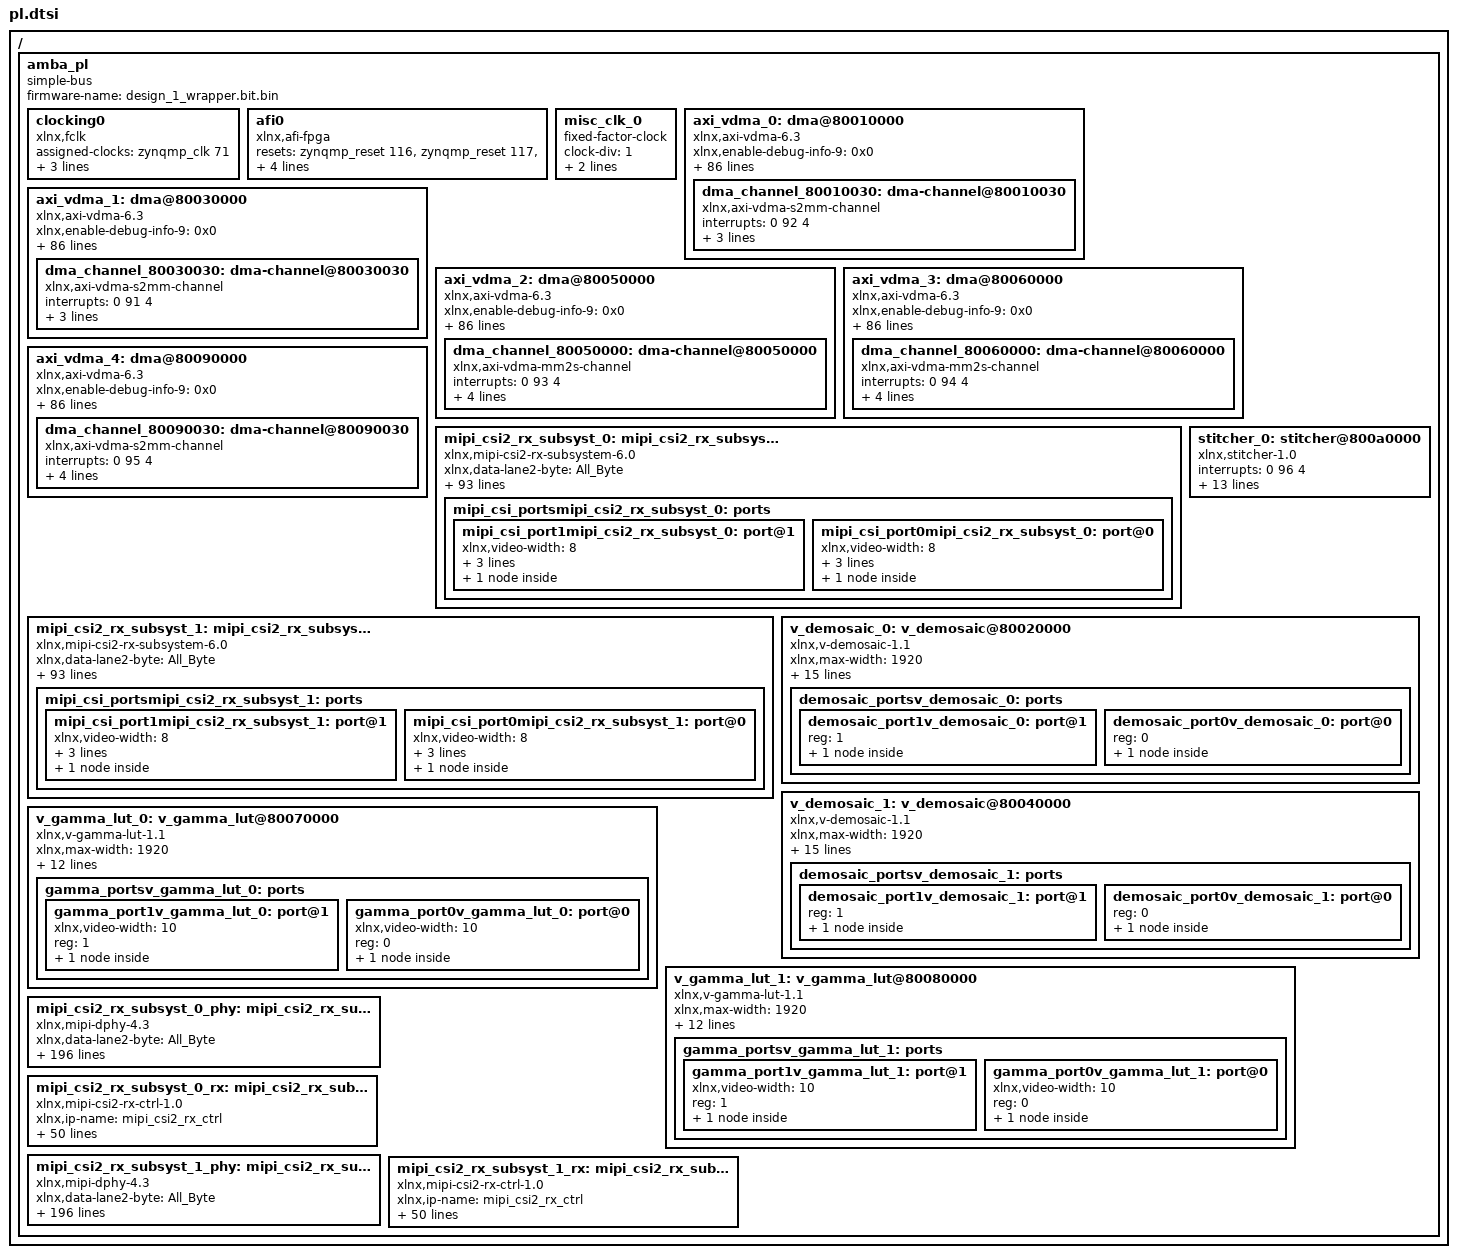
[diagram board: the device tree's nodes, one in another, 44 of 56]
/ {
	amba_pl: amba_pl {
		ranges;
		compatible = "simple-bus";
		#address-cells = <2>;
		#size-cells = <2>;
		firmware-name = "design_1_wrapper.bit.bin";
		clocking0: clocking0 {
			compatible = "xlnx,fclk";
			status = "okay";
			assigned-clocks = <&zynqmp_clk 71>;
			assigned-clock-rates = <149998505>;
			#clock-cells = <0>;
			clock-output-names = "fabric_clk";
			clocks = <&zynqmp_clk 71>;
		};
		afi0: afi0 {
			status = "okay";
			compatible = "xlnx,afi-fpga";
			resets = <&zynqmp_reset 116>, <&zynqmp_reset 117>, <&zynqmp_reset 118>, <&zynqmp_reset 119>;
			config-afi = < 0 0>, <1 0>, <2 0>, <3 0>, <4 0>, <5 0>, <6 0>, <7 0>, <8 0>, <9 0>, <10 0>, <11 0>, <12 0>, <13 0>, <14 0xa00>, <15 0x000>;
		};
		misc_clk_0: misc_clk_0 {
			clock-div = <1>;
			compatible = "fixed-factor-clock";
			clock-mult = <1>;
			clocks = <&zynqmp_clk 71>;
			#clock-cells = <0>;
		};
		axi_vdma_0: dma@80010000 {
			xlnx,enable-debug-info-9 = <0x0>;
			xlnx,enable-s2mm-frm-counter = <1>;
			xlnx,enable-mm2s-delay-counter = <1>;
			xlnx,dlytmr-resolution = <125>;
			xlnx,enable-s2mm-buf-full = <0>;
			xlnx,ip-name = "axi_vdma";
			xlnx,s2mm-genlock-num-masters = <1>;
			reg = <0x0 0x80010000 0x0 0x10000>;
			xlnx,enable-s2mm-fsync-out = <0>;
			xlnx,use-mm2s-fsync = <0>;
			xlnx,s2mm-linebuffer-thresh = <4>;
			xlnx,enable-mm2s-frm-counter = <1>;
			xlnx,m-axis-mm2s-tdata-width = <32>;
			xlnx,enable-all = <0>;
			xlnx,dynamic-resolution = <1>;
			xlnx,enable-s2mm-rst-out = <0>;
			interrupt-names = "s2mm_introut";
			xlnx,s2mm-sof-enable = <0x1>;
			xlnx,mm2s-genlock-num-masters = <1>;
			xlnx,enable-mm2s-fsync-out = <0>;
			xlnx,mm2s-linebuffer-thresh = <4>;
			compatible = "xlnx,axi-vdma-6.3" , "xlnx,axi-vdma-1.00.a";
			xlnx,enable-tstvec = <0>;
			interrupt-parent = <&imux>;
			xlnx,s2mm-max-burst-length = <128>;
			xlnx,enable-mm2s-rst-out = <0>;
			xlnx,mm2s-sof-enable = <1>;
			xlnx,include-s2mm-dre = <0x1>;
			xlnx,enable-s2mm-frmstr-reg = <0>;
			xlnx,m-axi-s2mm-data-width = <64>;
			xlnx,enable-s2mm-sts-reg = <0>;
			xlnx,mm2s-max-burst-length = <8>;
			status = "okay";
			xlnx,include-mm2s-dre = <0x0>;
			xlnx,name = "axi_vdma_0";
			xlnx,enable-mm2s-frmstr-reg = <0>;
			interrupts = < 0 92 4 >;
			xlnx,m-axi-mm2s-data-width = <64>;
			xlnx,flush-on-fsync = <0x1>;
			xlnx,include-s2mm-sf = <1>;
			xlnx,single-interface = <0>;
			xlnx,s2mm-linebuffer-depth = <0x400>;
			xlnx,include-s2mm = <0x1>;
			xlnx,addr-width = <32>;
			clocks = <&zynqmp_clk 71>, <&zynqmp_clk 71>, <&zynqmp_clk 71>;
			xlnx,s-axis-s2mm-tdata-width = <32>;
			xlnx,enable-debug-info-10 = <0>;
			xlnx,addrwidth = <0x20>;
			xlnx,enable-debug-info-11 = <0>;
			xlnx,edk-iptype = "PERIPHERAL";
			xlnx,enable-debug-info-12 = <0>;
			xlnx,use-fsync = <1>;
			xlnx,s2mm-genlock-repeat-en = <1>;
			xlnx,enable-debug-info-13 = <0x0>;
			xlnx,enable-vert-flip = <0x0>;
			xlnx,include-mm2s-sf = <0>;
			xlnx,enable-debug-info-14 = <0x1>;
			xlnx,include-internal-genlock = <0x1>;
			clock-names = "m_axi_s2mm_aclk" , "s_axi_lite_aclk" , "s_axis_s2mm_aclk";
			xlnx,enable-debug-info-15 = <0x1>;
			xlnx,mm2s-linebuffer-depth = <0x200>;
			xlnx,include-mm2s = <0x0>;
			xlnx,s2mm-genlock-mode = <0x0>;
			xlnx,flush-fsync = <0x1>;
			xlnx,select-xpm = <0>;
			xlnx,s2mm-data-width = <0x40>;
			xlnx,num-fstores = <0x3>;
			xlnx,enable-s2mm-param-updt = <0>;
			xlnx,enable-vidparam-reads = <0x1>;
			xlnx,mm2s-genlock-repeat-en = <0>;
			xlnx,prmry-is-aclk-async = <0>;
			xlnx,s2mm-tdata-width = <0x20>;
			#dma-cells = <1>;
			xlnx,enable-vidprmtr-reads = <1>;
			xlnx,mm2s-genlock-mode = <0x0>;
			xlnx,enable-debug-info-0 = <0>;
			xlnx,enable-debug-all = <0x0>;
			xlnx,enable-debug-info-1 = <0x0>;
			xlnx,mm2s-data-width = <0x40>;
			xlnx,enable-debug-info-2 = <0>;
			xlnx,enable-mm2s-param-updt = <0>;
			xlnx,enable-debug-info-3 = <0>;
			xlnx,enable-s2mm-delay-counter = <1>;
			xlnx,enable-debug-info-4 = <0>;
			xlnx,enable-debug-info-5 = <0x0>;
			xlnx,mm2s-tdata-width = <0x20>;
			xlnx,enable-debug-info-6 = <0x1>;
			xlnx,enable-debug-info-7 = <0x1>;
			xlnx,use-s2mm-fsync = <2>;
			xlnx,enable-debug-info-8 = <0>;
			xlnx,enable-mm2s-buf-empty = <0>;
			dma_channel_80010030: dma-channel@80010030 {
				interrupts = < 0 92 4 >;
				xlnx,datawidth = <0x20>;
				xlnx,device-id = <0x0>;
				compatible = "xlnx,axi-vdma-s2mm-channel";
				xlnx,include-dre;
			};
		};
		axi_vdma_1: dma@80030000 {
			xlnx,enable-debug-info-9 = <0x0>;
			xlnx,enable-s2mm-frm-counter = <1>;
			xlnx,enable-mm2s-delay-counter = <1>;
			xlnx,dlytmr-resolution = <125>;
			xlnx,enable-s2mm-buf-full = <0>;
			xlnx,ip-name = "axi_vdma";
			xlnx,s2mm-genlock-num-masters = <1>;
			reg = <0x0 0x80030000 0x0 0x10000>;
			xlnx,enable-s2mm-fsync-out = <0>;
			xlnx,use-mm2s-fsync = <0>;
			xlnx,s2mm-linebuffer-thresh = <4>;
			xlnx,enable-mm2s-frm-counter = <1>;
			xlnx,m-axis-mm2s-tdata-width = <32>;
			xlnx,enable-all = <0>;
			xlnx,dynamic-resolution = <1>;
			xlnx,enable-s2mm-rst-out = <0>;
			interrupt-names = "s2mm_introut";
			xlnx,s2mm-sof-enable = <0x1>;
			xlnx,mm2s-genlock-num-masters = <1>;
			xlnx,enable-mm2s-fsync-out = <0>;
			xlnx,mm2s-linebuffer-thresh = <4>;
			compatible = "xlnx,axi-vdma-6.3" , "xlnx,axi-vdma-1.00.a";
			xlnx,enable-tstvec = <0>;
			interrupt-parent = <&imux>;
			xlnx,s2mm-max-burst-length = <128>;
			xlnx,enable-mm2s-rst-out = <0>;
			xlnx,mm2s-sof-enable = <1>;
			xlnx,include-s2mm-dre = <0x1>;
			xlnx,enable-s2mm-frmstr-reg = <0>;
			xlnx,m-axi-s2mm-data-width = <64>;
			xlnx,enable-s2mm-sts-reg = <0>;
			xlnx,mm2s-max-burst-length = <8>;
			status = "okay";
			xlnx,include-mm2s-dre = <0x0>;
			xlnx,name = "axi_vdma_1";
			xlnx,enable-mm2s-frmstr-reg = <0>;
			interrupts = < 0 91 4 >;
			xlnx,m-axi-mm2s-data-width = <64>;
			xlnx,flush-on-fsync = <0x1>;
			xlnx,include-s2mm-sf = <1>;
			xlnx,single-interface = <0>;
			xlnx,s2mm-linebuffer-depth = <0x400>;
			xlnx,include-s2mm = <0x1>;
			xlnx,addr-width = <32>;
			clocks = <&zynqmp_clk 71>, <&zynqmp_clk 71>, <&zynqmp_clk 71>;
			xlnx,s-axis-s2mm-tdata-width = <32>;
			xlnx,enable-debug-info-10 = <0>;
			xlnx,addrwidth = <0x20>;
			xlnx,enable-debug-info-11 = <0>;
			xlnx,edk-iptype = "PERIPHERAL";
			xlnx,enable-debug-info-12 = <0>;
			xlnx,use-fsync = <1>;
			xlnx,s2mm-genlock-repeat-en = <1>;
			xlnx,enable-debug-info-13 = <0x0>;
			xlnx,enable-vert-flip = <0x0>;
			xlnx,include-mm2s-sf = <0>;
			xlnx,enable-debug-info-14 = <0x1>;
			xlnx,include-internal-genlock = <0x1>;
			clock-names = "m_axi_s2mm_aclk" , "s_axi_lite_aclk" , "s_axis_s2mm_aclk";
			xlnx,enable-debug-info-15 = <0x1>;
			xlnx,mm2s-linebuffer-depth = <0x200>;
			xlnx,include-mm2s = <0x0>;
			xlnx,s2mm-genlock-mode = <0x0>;
			xlnx,flush-fsync = <0x1>;
			xlnx,select-xpm = <0>;
			xlnx,s2mm-data-width = <0x40>;
			xlnx,num-fstores = <0x3>;
			xlnx,enable-s2mm-param-updt = <0>;
			xlnx,enable-vidparam-reads = <0x1>;
			xlnx,mm2s-genlock-repeat-en = <0>;
			xlnx,prmry-is-aclk-async = <0>;
			xlnx,s2mm-tdata-width = <0x20>;
			#dma-cells = <1>;
			xlnx,enable-vidprmtr-reads = <1>;
			xlnx,mm2s-genlock-mode = <0x0>;
			xlnx,enable-debug-info-0 = <0>;
			xlnx,enable-debug-all = <0x0>;
			xlnx,enable-debug-info-1 = <0x0>;
			xlnx,mm2s-data-width = <0x40>;
			xlnx,enable-debug-info-2 = <0>;
			xlnx,enable-mm2s-param-updt = <0>;
			xlnx,enable-debug-info-3 = <0>;
			xlnx,enable-s2mm-delay-counter = <1>;
			xlnx,enable-debug-info-4 = <0>;
			xlnx,enable-debug-info-5 = <0x0>;
			xlnx,mm2s-tdata-width = <0x20>;
			xlnx,enable-debug-info-6 = <0x1>;
			xlnx,enable-debug-info-7 = <0x1>;
			xlnx,use-s2mm-fsync = <2>;
			xlnx,enable-debug-info-8 = <0>;
			xlnx,enable-mm2s-buf-empty = <0>;
			dma_channel_80030030: dma-channel@80030030 {
				interrupts = < 0 91 4 >;
				xlnx,datawidth = <0x20>;
				xlnx,device-id = <0x1>;
				compatible = "xlnx,axi-vdma-s2mm-channel";
				xlnx,include-dre;
			};
		};
		axi_vdma_2: dma@80050000 {
			xlnx,enable-debug-info-9 = <0x0>;
			xlnx,enable-s2mm-frm-counter = <1>;
			xlnx,enable-mm2s-delay-counter = <1>;
			xlnx,dlytmr-resolution = <125>;
			xlnx,enable-s2mm-buf-full = <0>;
			xlnx,ip-name = "axi_vdma";
			xlnx,s2mm-genlock-num-masters = <1>;
			reg = <0x0 0x80050000 0x0 0x10000>;
			xlnx,enable-s2mm-fsync-out = <0>;
			xlnx,use-mm2s-fsync = <0>;
			xlnx,s2mm-linebuffer-thresh = <4>;
			xlnx,enable-mm2s-frm-counter = <1>;
			xlnx,m-axis-mm2s-tdata-width = <32>;
			xlnx,enable-all = <0>;
			xlnx,dynamic-resolution = <1>;
			xlnx,enable-s2mm-rst-out = <0>;
			interrupt-names = "mm2s_introut";
			xlnx,s2mm-sof-enable = <0x1>;
			xlnx,mm2s-genlock-num-masters = <1>;
			xlnx,enable-mm2s-fsync-out = <0>;
			xlnx,mm2s-linebuffer-thresh = <4>;
			compatible = "xlnx,axi-vdma-6.3" , "xlnx,axi-vdma-1.00.a";
			xlnx,enable-tstvec = <0>;
			interrupt-parent = <&imux>;
			xlnx,s2mm-max-burst-length = <8>;
			xlnx,enable-mm2s-rst-out = <0>;
			xlnx,mm2s-sof-enable = <1>;
			xlnx,include-s2mm-dre = <0x0>;
			xlnx,enable-s2mm-frmstr-reg = <0>;
			xlnx,m-axi-s2mm-data-width = <64>;
			xlnx,enable-s2mm-sts-reg = <0>;
			xlnx,mm2s-max-burst-length = <128>;
			status = "okay";
			xlnx,include-mm2s-dre = <0x1>;
			xlnx,name = "axi_vdma_2";
			xlnx,enable-mm2s-frmstr-reg = <0>;
			interrupts = < 0 93 4 >;
			xlnx,m-axi-mm2s-data-width = <64>;
			xlnx,flush-on-fsync = <0x1>;
			xlnx,include-s2mm-sf = <1>;
			xlnx,single-interface = <0>;
			xlnx,s2mm-linebuffer-depth = <0x200>;
			xlnx,include-s2mm = <0x0>;
			xlnx,addr-width = <32>;
			clocks = <&zynqmp_clk 71>, <&zynqmp_clk 71>, <&zynqmp_clk 71>;
			xlnx,s-axis-s2mm-tdata-width = <32>;
			xlnx,enable-debug-info-10 = <0>;
			xlnx,addrwidth = <0x20>;
			xlnx,enable-debug-info-11 = <0>;
			xlnx,edk-iptype = "PERIPHERAL";
			xlnx,enable-debug-info-12 = <0>;
			xlnx,use-fsync = <1>;
			xlnx,s2mm-genlock-repeat-en = <1>;
			xlnx,enable-debug-info-13 = <0x0>;
			xlnx,enable-vert-flip = <0x0>;
			xlnx,include-mm2s-sf = <0>;
			xlnx,enable-debug-info-14 = <0x1>;
			xlnx,include-internal-genlock = <0x1>;
			clock-names = "m_axi_mm2s_aclk" , "m_axis_mm2s_aclk" , "s_axi_lite_aclk";
			xlnx,enable-debug-info-15 = <0x1>;
			xlnx,mm2s-linebuffer-depth = <0x400>;
			xlnx,include-mm2s = <0x1>;
			xlnx,s2mm-genlock-mode = <0x0>;
			xlnx,flush-fsync = <0x1>;
			xlnx,select-xpm = <0>;
			xlnx,s2mm-data-width = <0x40>;
			xlnx,num-fstores = <0x3>;
			xlnx,enable-s2mm-param-updt = <0>;
			xlnx,enable-vidparam-reads = <0x1>;
			xlnx,mm2s-genlock-repeat-en = <0>;
			xlnx,prmry-is-aclk-async = <0>;
			xlnx,s2mm-tdata-width = <0x20>;
			#dma-cells = <1>;
			xlnx,enable-vidprmtr-reads = <1>;
			xlnx,mm2s-genlock-mode = <0x3>;
			xlnx,enable-debug-info-0 = <0>;
			xlnx,enable-debug-all = <0x0>;
			xlnx,enable-debug-info-1 = <0x0>;
			xlnx,mm2s-data-width = <0x40>;
			xlnx,enable-debug-info-2 = <0>;
			xlnx,enable-mm2s-param-updt = <0>;
			xlnx,enable-debug-info-3 = <0>;
			xlnx,enable-s2mm-delay-counter = <1>;
			xlnx,enable-debug-info-4 = <0>;
			xlnx,enable-debug-info-5 = <0x0>;
			xlnx,mm2s-tdata-width = <0x20>;
			xlnx,enable-debug-info-6 = <0x1>;
			xlnx,enable-debug-info-7 = <0x1>;
			xlnx,use-s2mm-fsync = <2>;
			xlnx,enable-debug-info-8 = <0>;
			xlnx,enable-mm2s-buf-empty = <0>;
			dma_channel_80050000: dma-channel@80050000 {
				interrupts = < 0 93 4 >;
				xlnx,datawidth = <0x20>;
				xlnx,device-id = <0x2>;
				compatible = "xlnx,axi-vdma-mm2s-channel";
				xlnx,include-dre;
				xlnx,genlock-mode;
			};
		};
		axi_vdma_3: dma@80060000 {
			xlnx,enable-debug-info-9 = <0x0>;
			xlnx,enable-s2mm-frm-counter = <1>;
			xlnx,enable-mm2s-delay-counter = <1>;
			xlnx,dlytmr-resolution = <125>;
			xlnx,enable-s2mm-buf-full = <0>;
			xlnx,ip-name = "axi_vdma";
			xlnx,s2mm-genlock-num-masters = <1>;
			reg = <0x0 0x80060000 0x0 0x10000>;
			xlnx,enable-s2mm-fsync-out = <0>;
			xlnx,use-mm2s-fsync = <0>;
			xlnx,s2mm-linebuffer-thresh = <4>;
			xlnx,enable-mm2s-frm-counter = <1>;
			xlnx,m-axis-mm2s-tdata-width = <32>;
			xlnx,enable-all = <0>;
			xlnx,dynamic-resolution = <1>;
			xlnx,enable-s2mm-rst-out = <0>;
			interrupt-names = "mm2s_introut";
			xlnx,s2mm-sof-enable = <0x1>;
			xlnx,mm2s-genlock-num-masters = <1>;
			xlnx,enable-mm2s-fsync-out = <0>;
			xlnx,mm2s-linebuffer-thresh = <4>;
			compatible = "xlnx,axi-vdma-6.3" , "xlnx,axi-vdma-1.00.a";
			xlnx,enable-tstvec = <0>;
			interrupt-parent = <&imux>;
			xlnx,s2mm-max-burst-length = <8>;
			xlnx,enable-mm2s-rst-out = <0>;
			xlnx,mm2s-sof-enable = <1>;
			xlnx,include-s2mm-dre = <0x0>;
			xlnx,enable-s2mm-frmstr-reg = <0>;
			xlnx,m-axi-s2mm-data-width = <64>;
			xlnx,enable-s2mm-sts-reg = <0>;
			xlnx,mm2s-max-burst-length = <128>;
			status = "okay";
			xlnx,include-mm2s-dre = <0x1>;
			xlnx,name = "axi_vdma_3";
			xlnx,enable-mm2s-frmstr-reg = <0>;
			interrupts = < 0 94 4 >;
			xlnx,m-axi-mm2s-data-width = <64>;
			xlnx,flush-on-fsync = <0x1>;
			xlnx,include-s2mm-sf = <1>;
			xlnx,single-interface = <0>;
			xlnx,s2mm-linebuffer-depth = <0x200>;
			xlnx,include-s2mm = <0x0>;
			xlnx,addr-width = <32>;
			clocks = <&zynqmp_clk 71>, <&zynqmp_clk 71>, <&zynqmp_clk 71>;
			xlnx,s-axis-s2mm-tdata-width = <32>;
			xlnx,enable-debug-info-10 = <0>;
			xlnx,addrwidth = <0x20>;
			xlnx,enable-debug-info-11 = <0>;
			xlnx,edk-iptype = "PERIPHERAL";
			xlnx,enable-debug-info-12 = <0>;
			xlnx,use-fsync = <1>;
			xlnx,s2mm-genlock-repeat-en = <1>;
			xlnx,enable-debug-info-13 = <0x0>;
			xlnx,enable-vert-flip = <0x0>;
			xlnx,include-mm2s-sf = <0>;
			xlnx,enable-debug-info-14 = <0x1>;
			xlnx,include-internal-genlock = <0x1>;
			clock-names = "m_axi_mm2s_aclk" , "m_axis_mm2s_aclk" , "s_axi_lite_aclk";
			xlnx,enable-debug-info-15 = <0x1>;
			xlnx,mm2s-linebuffer-depth = <0x400>;
			xlnx,include-mm2s = <0x1>;
			xlnx,s2mm-genlock-mode = <0x0>;
			xlnx,flush-fsync = <0x1>;
			xlnx,select-xpm = <0>;
			xlnx,s2mm-data-width = <0x40>;
			xlnx,num-fstores = <0x3>;
			xlnx,enable-s2mm-param-updt = <0>;
			xlnx,enable-vidparam-reads = <0x1>;
			xlnx,mm2s-genlock-repeat-en = <0>;
			xlnx,prmry-is-aclk-async = <0>;
			xlnx,s2mm-tdata-width = <0x20>;
			#dma-cells = <1>;
			xlnx,enable-vidprmtr-reads = <1>;
			xlnx,mm2s-genlock-mode = <0x3>;
			xlnx,enable-debug-info-0 = <0>;
			xlnx,enable-debug-all = <0x0>;
			xlnx,enable-debug-info-1 = <0x0>;
			xlnx,mm2s-data-width = <0x40>;
			xlnx,enable-debug-info-2 = <0>;
			xlnx,enable-mm2s-param-updt = <0>;
			xlnx,enable-debug-info-3 = <0>;
			xlnx,enable-s2mm-delay-counter = <1>;
			xlnx,enable-debug-info-4 = <0>;
			xlnx,enable-debug-info-5 = <0x0>;
			xlnx,mm2s-tdata-width = <0x20>;
			xlnx,enable-debug-info-6 = <0x1>;
			xlnx,enable-debug-info-7 = <0x1>;
			xlnx,use-s2mm-fsync = <2>;
			xlnx,enable-debug-info-8 = <0>;
			xlnx,enable-mm2s-buf-empty = <0>;
			dma_channel_80060000: dma-channel@80060000 {
				interrupts = < 0 94 4 >;
				xlnx,datawidth = <0x20>;
				xlnx,device-id = <0x3>;
				compatible = "xlnx,axi-vdma-mm2s-channel";
				xlnx,include-dre;
				xlnx,genlock-mode;
			};
		};
		axi_vdma_4: dma@80090000 {
			xlnx,enable-debug-info-9 = <0x0>;
			xlnx,enable-s2mm-frm-counter = <1>;
			xlnx,enable-mm2s-delay-counter = <1>;
			xlnx,dlytmr-resolution = <125>;
			xlnx,enable-s2mm-buf-full = <0>;
			xlnx,ip-name = "axi_vdma";
			xlnx,s2mm-genlock-num-masters = <1>;
			reg = <0x0 0x80090000 0x0 0x10000>;
			xlnx,enable-s2mm-fsync-out = <0>;
			xlnx,use-mm2s-fsync = <0>;
			xlnx,s2mm-linebuffer-thresh = <4>;
			xlnx,enable-mm2s-frm-counter = <1>;
			xlnx,m-axis-mm2s-tdata-width = <32>;
			xlnx,enable-all = <0>;
			xlnx,dynamic-resolution = <1>;
			xlnx,enable-s2mm-rst-out = <0>;
			interrupt-names = "s2mm_introut";
			xlnx,s2mm-sof-enable = <0x1>;
			xlnx,mm2s-genlock-num-masters = <1>;
			xlnx,enable-mm2s-fsync-out = <0>;
			xlnx,mm2s-linebuffer-thresh = <4>;
			compatible = "xlnx,axi-vdma-6.3" , "xlnx,axi-vdma-1.00.a";
			xlnx,enable-tstvec = <0>;
			interrupt-parent = <&imux>;
			xlnx,s2mm-max-burst-length = <128>;
			xlnx,enable-mm2s-rst-out = <0>;
			xlnx,mm2s-sof-enable = <1>;
			xlnx,include-s2mm-dre = <0x1>;
			xlnx,enable-s2mm-frmstr-reg = <0>;
			xlnx,m-axi-s2mm-data-width = <64>;
			xlnx,enable-s2mm-sts-reg = <0>;
			xlnx,mm2s-max-burst-length = <8>;
			status = "okay";
			xlnx,include-mm2s-dre = <0x0>;
			xlnx,name = "axi_vdma_4";
			xlnx,enable-mm2s-frmstr-reg = <0>;
			interrupts = < 0 95 4 >;
			xlnx,m-axi-mm2s-data-width = <64>;
			xlnx,flush-on-fsync = <0x1>;
			xlnx,include-s2mm-sf = <1>;
			xlnx,single-interface = <0>;
			xlnx,s2mm-linebuffer-depth = <0x400>;
			xlnx,include-s2mm = <0x1>;
			xlnx,addr-width = <32>;
			clocks = <&zynqmp_clk 71>, <&zynqmp_clk 71>, <&zynqmp_clk 71>;
			xlnx,s-axis-s2mm-tdata-width = <32>;
			xlnx,enable-debug-info-10 = <0>;
			xlnx,addrwidth = <0x20>;
			xlnx,enable-debug-info-11 = <0>;
			xlnx,edk-iptype = "PERIPHERAL";
			xlnx,enable-debug-info-12 = <0>;
			xlnx,use-fsync = <1>;
			xlnx,s2mm-genlock-repeat-en = <1>;
			xlnx,enable-debug-info-13 = <0x0>;
			xlnx,enable-vert-flip = <0x0>;
			xlnx,include-mm2s-sf = <0>;
			xlnx,enable-debug-info-14 = <0x1>;
			xlnx,include-internal-genlock = <0x1>;
			clock-names = "m_axi_s2mm_aclk" , "s_axi_lite_aclk" , "s_axis_s2mm_aclk";
			xlnx,enable-debug-info-15 = <0x1>;
			xlnx,mm2s-linebuffer-depth = <0x200>;
			xlnx,include-mm2s = <0x0>;
			xlnx,s2mm-genlock-mode = <0x2>;
			xlnx,flush-fsync = <0x1>;
			xlnx,select-xpm = <0>;
			xlnx,s2mm-data-width = <0x40>;
			xlnx,num-fstores = <0x3>;
			xlnx,enable-s2mm-param-updt = <0>;
			xlnx,enable-vidparam-reads = <0x1>;
			xlnx,mm2s-genlock-repeat-en = <0>;
			xlnx,prmry-is-aclk-async = <0>;
			xlnx,s2mm-tdata-width = <0x20>;
			#dma-cells = <1>;
			xlnx,enable-vidprmtr-reads = <1>;
			xlnx,mm2s-genlock-mode = <0x0>;
			xlnx,enable-debug-info-0 = <0>;
			xlnx,enable-debug-all = <0x0>;
			xlnx,enable-debug-info-1 = <0x0>;
			xlnx,mm2s-data-width = <0x40>;
			xlnx,enable-debug-info-2 = <0>;
			xlnx,enable-mm2s-param-updt = <0>;
			xlnx,enable-debug-info-3 = <0>;
			xlnx,enable-s2mm-delay-counter = <1>;
			xlnx,enable-debug-info-4 = <0>;
			xlnx,enable-debug-info-5 = <0x0>;
			xlnx,mm2s-tdata-width = <0x20>;
			xlnx,enable-debug-info-6 = <0x1>;
			xlnx,enable-debug-info-7 = <0x1>;
			xlnx,use-s2mm-fsync = <0>;
			xlnx,enable-debug-info-8 = <0>;
			xlnx,enable-mm2s-buf-empty = <0>;
			dma_channel_80090030: dma-channel@80090030 {
				interrupts = < 0 95 4 >;
				xlnx,datawidth = <0x20>;
				xlnx,device-id = <0x4>;
				compatible = "xlnx,axi-vdma-s2mm-channel";
				xlnx,include-dre;
				xlnx,genlock-mode;
			};
		};
		mipi_csi2_rx_subsyst_0: mipi_csi2_rx_subsystem@80000000 {
			xlnx,data-lane2-byte = "All_Byte";
			xlnx,dpy-en-reg-if = <1>;
			xlnx,cmn-vc = <4>;
			xlnx,dphy-lanes = <2>;
			xlnx,ip-name = "mipi_csi2_rx_subsystem";
			reg = <0x0 0x80000000 0x0 0x2000>;
			xlnx,vfb-tu-width = <1>;
			xlnx,ppc = <1>;
			xlnx,csi-buf-depth = <2048>;
			xlnx,exdes-fmc = "LI-IMX274MIPI-FMC , V1.0 , Single , Sensor";
			xlnx,supportlevel = <1>;
			xlnx,clk-lane-io-loc-name = "IO_L1P_T0L_N0_DBC_64";
			xlnx,max-lanes = <2>;
			xlnx,cmn-inc-iic = <0>;
			xlnx,clk-lane-io-loc = "AC9";
			xlnx,esc-timeout = <25600>;
			interrupt-names = "csirxss_csi_irq";
			xlnx,cmn-inc-vfb;
			xlnx,axis-tuser-width = <96>;
			compatible = "xlnx,mipi-csi2-rx-subsystem-6.0" , "xlnx,mipi-csi2-rx-subsystem-5.0";
			xlnx,en-active-lanes;
			xlnx,idly-tap = <1>;
			dphy-present = <1>;
			xlnx,cmn-num-pixels = <1>;
			xlnx,cmn-proj-family = <1>;
			xlnx,csi2rx-dbg = <0>;
			xlnx,fifo-rd-en-control;
			xlnx,vfb;
			interrupt-parent = <&imux>;
			xlnx,data-lane1-io-loc-name = "IO_L3P_T0L_N4_AD15P_64";
			dphy-connected = <&mipi_csi2_rx_subsyst_0_phy>;
			xlnx,hs-timeout = <65541>;
			xlnx,data-lane3-io-loc-name = "None";
			xlnx,ext-mmcm = <0>;
			xlnx,data-lane1-byte = "All_Byte";
			xlnx,cal-mode = "NONE";
			xlnx,mipi-rx-phy-mode = <1>;
			status = "okay";
			xlnx,data-lane0-io-position = <2>;
			xlnx,exdes-board = "ZCU102";
			xlnx,data-lane2-io-position = <6>;
			xlnx,vc = <4>;
			xlnx,en-vcx = <0>;
			xlnx,name = "mipi_csi2_rx_subsyst_0";
			xlnx,csi-emb-non-img = <0>;
			interrupts = < 0 89 4 >;
			xlnx,dphyrx-board-interface = "Custom";
			xlnx,data-lane3-io-loc = "None";
			xlnx,hs-settle-ns = <145>;
			clocks = <&zynqmp_clk 72>, <&zynqmp_clk 71>, <&zynqmp_clk 71>;
			xlnx,data-lane2-io-loc = "None";
			xlnx,mipi-slv-int = <0>;
			xlnx,cmn-fifo-rd-en-cntrl;
			xlnx,data-lane3-byte = "All_Byte";
			xlnx,axis-tdest-width = <4>;
			xlnx,phy-mode = "DPHY";
			xlnx,stretch-line-rate = <3500>;
			xlnx,en-csi-v2 = <0>;
			xlnx,edk-iptype = "PERIPHERAL";
			xlnx,init = <100000>;
			xlnx,cmn-pxl-format = <0x2b>;
			xlnx,int-qor-check = <0>;
			clock-names = "dphy_clk_200M" , "lite_aclk" , "video_aclk";
			xlnx,data-lane1-io-loc = "AB8";
			xlnx,data-lane0-byte = "All_Byte";
			xlnx,ooc-vid-clk = <0x65b710>;
			csirx-present = <1>;
			xlnx,yuv420-buf-dpth = <128>;
			xlnx,hp-io-bank-selection = <64>;
			xlnx,idly-group-name = "mipi_csi2rx_idly_group";
			xlnx,lprx-disable-extport = <0>;
			csirx-connected = <&mipi_csi2_rx_subsyst_0_rx>;
			xlnx,highaddr = <0x80001fff>;
			xlnx,cmn-num-lanes = <2>;
			xlnx,exdes-config = "MIPI_Video_Pipe_Camera_to_Display";
			xlnx,exdesboard-version = <2>;
			xlnx,dphy-preset = "CSI2RX_XLNX";
			xlnx,data-lane0-io-loc-name = "IO_L2P_T0L_N2_64";
			xlnx,csi-pxl-format = <0x2b>;
			xlnx,clk-lane-io-position = <0>;
			xlnx,en-7s-linerate-check;
			xlnx,data-lane2-io-loc-name = "None";
			xlnx,data-lane0-io-loc = "AE9";
			xlnx,inc-phy;
			xlnx,hs-line-rate = <1000>;
			rxphy-present = <0>;
			xlnx,dpy-line-rate = <1000>;
			xlnx,csi-en-crc = <1>;
			xlnx,axis-tdata-width = <32>;
			xlnx,csi-controller-reg-if;
			xlnx,data-lane1-io-position = <4>;
			xlnx,dphy-mode = "SLAVE";
			xlnx,data-lane3-io-position = <8>;
			mipi_csi_portsmipi_csi2_rx_subsyst_0: ports {
				#address-cells = <1>;
				#size-cells = <0>;
				mipi_csi_port1mipi_csi2_rx_subsyst_0: port@1 {
					xlnx,video-width = <8>;
					reg = <1>;
					xlnx,video-format = <12>;
					xlnx,cfa-pattern = "rggb";
					mipi_csirx_outmipi_csi2_rx_subsyst_0: endpoint {
						remote-endpoint = <&v_demosaic_0mipi_csi2_rx_subsyst_0>;
					};
				};
				mipi_csi_port0mipi_csi2_rx_subsyst_0: port@0 {
					xlnx,video-width = <8>;
					reg = <0>;
					xlnx,video-format = <12>;
					xlnx,cfa-pattern = "rggb";
					mipi_csi_inmipi_csi2_rx_subsyst_0: endpoint {
						data-lanes = < 1 2 >;
					};
				};
			};
		};
		mipi_csi2_rx_subsyst_1: mipi_csi2_rx_subsystem@80002000 {
			xlnx,data-lane2-byte = "All_Byte";
			xlnx,dpy-en-reg-if = <1>;
			xlnx,cmn-vc = <4>;
			xlnx,dphy-lanes = <2>;
			xlnx,ip-name = "mipi_csi2_rx_subsystem";
			reg = <0x0 0x80002000 0x0 0x2000>;
			xlnx,vfb-tu-width = <1>;
			xlnx,ppc = <1>;
			xlnx,csi-buf-depth = <2048>;
			xlnx,exdes-fmc = "LI-IMX274MIPI-FMC , V1.0 , Single , Sensor";
			xlnx,supportlevel = <1>;
			xlnx,clk-lane-io-loc-name = "IO_L1P_T0L_N0_DBC_65";
			xlnx,max-lanes = <2>;
			xlnx,cmn-inc-iic = <0>;
			xlnx,clk-lane-io-loc = "W8";
			xlnx,esc-timeout = <25600>;
			interrupt-names = "csirxss_csi_irq";
			xlnx,cmn-inc-vfb;
			xlnx,axis-tuser-width = <96>;
			compatible = "xlnx,mipi-csi2-rx-subsystem-6.0" , "xlnx,mipi-csi2-rx-subsystem-5.0";
			xlnx,en-active-lanes;
			xlnx,idly-tap = <1>;
			dphy-present = <1>;
			xlnx,cmn-num-pixels = <1>;
			xlnx,cmn-proj-family = <1>;
			xlnx,csi2rx-dbg = <0>;
			xlnx,fifo-rd-en-control;
			xlnx,vfb;
			interrupt-parent = <&imux>;
			xlnx,data-lane1-io-loc-name = "IO_L3P_T0L_N4_AD15P_65";
			dphy-connected = <&mipi_csi2_rx_subsyst_1_phy>;
			xlnx,hs-timeout = <65541>;
			xlnx,data-lane3-io-loc-name = "None";
			xlnx,ext-mmcm = <0>;
			xlnx,data-lane1-byte = "All_Byte";
			xlnx,cal-mode = "NONE";
			xlnx,mipi-rx-phy-mode = <1>;
			status = "okay";
			xlnx,data-lane0-io-position = <2>;
			xlnx,exdes-board = "ZCU102";
			xlnx,data-lane2-io-position = <6>;
			xlnx,vc = <4>;
			xlnx,en-vcx = <0>;
			xlnx,name = "mipi_csi2_rx_subsyst_1";
			xlnx,csi-emb-non-img = <0>;
			interrupts = < 0 90 4 >;
			xlnx,dphyrx-board-interface = "Custom";
			xlnx,data-lane3-io-loc = "None";
			xlnx,hs-settle-ns = <145>;
			clocks = <&zynqmp_clk 72>, <&zynqmp_clk 71>, <&zynqmp_clk 71>;
			xlnx,data-lane2-io-loc = "None";
			xlnx,mipi-slv-int = <0>;
			xlnx,cmn-fifo-rd-en-cntrl;
			xlnx,data-lane3-byte = "All_Byte";
			xlnx,axis-tdest-width = <4>;
			xlnx,phy-mode = "DPHY";
			xlnx,stretch-line-rate = <3500>;
			xlnx,en-csi-v2 = <0>;
			xlnx,edk-iptype = "PERIPHERAL";
			xlnx,init = <100000>;
			xlnx,cmn-pxl-format = <0x2b>;
			xlnx,int-qor-check = <0>;
			clock-names = "dphy_clk_200M" , "lite_aclk" , "video_aclk";
			xlnx,data-lane1-io-loc = "U8";
			xlnx,data-lane0-byte = "All_Byte";
			xlnx,ooc-vid-clk = <0x65b710>;
			csirx-present = <1>;
			xlnx,yuv420-buf-dpth = <128>;
			xlnx,hp-io-bank-selection = <65>;
			xlnx,idly-group-name = "mipi_csi2rx_idly_group";
			xlnx,lprx-disable-extport = <0>;
			csirx-connected = <&mipi_csi2_rx_subsyst_1_rx>;
			xlnx,highaddr = <0x80003fff>;
			xlnx,cmn-num-lanes = <2>;
			xlnx,exdes-config = "MIPI_Video_Pipe_Camera_to_Display";
			xlnx,exdesboard-version = <2>;
			xlnx,dphy-preset = "CSI2RX_XLNX";
			xlnx,data-lane0-io-loc-name = "IO_L2P_T0L_N2_65";
			xlnx,csi-pxl-format = <0x2b>;
			xlnx,clk-lane-io-position = <0>;
			xlnx,en-7s-linerate-check;
			xlnx,data-lane2-io-loc-name = "None";
			xlnx,data-lane0-io-loc = "U9";
			xlnx,inc-phy;
			xlnx,hs-line-rate = <1000>;
			rxphy-present = <0>;
			xlnx,dpy-line-rate = <1000>;
			xlnx,csi-en-crc = <1>;
			xlnx,axis-tdata-width = <32>;
			xlnx,csi-controller-reg-if;
			xlnx,data-lane1-io-position = <4>;
			xlnx,dphy-mode = "SLAVE";
			xlnx,data-lane3-io-position = <8>;
			mipi_csi_portsmipi_csi2_rx_subsyst_1: ports {
				#address-cells = <1>;
				#size-cells = <0>;
				mipi_csi_port1mipi_csi2_rx_subsyst_1: port@1 {
					xlnx,video-width = <8>;
					reg = <1>;
					xlnx,video-format = <12>;
					xlnx,cfa-pattern = "rggb";
					mipi_csirx_outmipi_csi2_rx_subsyst_1: endpoint {
						remote-endpoint = <&v_demosaic_1mipi_csi2_rx_subsyst_1>;
					};
				};
				mipi_csi_port0mipi_csi2_rx_subsyst_1: port@0 {
					xlnx,video-width = <8>;
					reg = <0>;
					xlnx,video-format = <12>;
					xlnx,cfa-pattern = "rggb";
					mipi_csi_inmipi_csi2_rx_subsyst_1: endpoint {
						data-lanes = < 1 2 >;
					};
				};
			};
		};
		stitcher_0: stitcher@800a0000 {
			interrupts = < 0 96 4 >;
			compatible = "xlnx,stitcher-1.0";
			xlnx,ii = "2083327 , ~ , 2084408";
			xlnx,machine = <64>;
			interrupt-parent = <&imux>;
			xlnx,ip-name = "stitcher";
			reg = <0x0 0x800a0000 0x0 0x10000>;
			clocks = <&zynqmp_clk 71>;
			xlnx,s-axi-ctrl-addr-width = <4>;
			xlnx,clk-period = <10>;
			xlnx,edk-iptype = "PERIPHERAL";
			status = "okay";
			clock-names = "ap_clk";
			interrupt-names = "interrupt";
			xlnx,combinational = <0>;
			xlnx,s-axi-ctrl-data-width = <32>;
			xlnx,latency = <2083326>;
			xlnx,name = "stitcher_0";
		};
		v_demosaic_0: v_demosaic@80020000 {
			compatible = "xlnx,v-demosaic-1.1" , "xlnx,v-demosaic";
			xlnx,max-width = <1920>;
			xlnx,max-height = <1080>;
			xlnx,max-rows = <1080>;
			xlnx,use-uram = <0>;
			xlnx,ip-name = "v_demosaic";
			reg = <0x0 0x80020000 0x0 0x10000>;
			clocks = <&zynqmp_clk 71>;
			xlnx,s-axi-ctrl-addr-width = <6>;
			xlnx,enable-zipper-removal;
			xlnx,samples-per-clock = <1>;
			xlnx,max-data-width = <10>;
			xlnx,edk-iptype = "PERIPHERAL";
			xlnx,max-cols = <1920>;
			status = "okay";
			clock-names = "ap_clk";
			xlnx,algorithm = <0>;
			xlnx,s-axi-ctrl-data-width = <32>;
			xlnx,name = "v_demosaic_0";
			demosaic_portsv_demosaic_0: ports {
				#address-cells = <1>;
				#size-cells = <0>;
				demosaic_port1v_demosaic_0: port@1 {
					reg = <1>;
					demo_outv_demosaic_0: endpoint {
						remote-endpoint = <&v_gamma_lut_0v_demosaic_0>;
					};
				};
				demosaic_port0v_demosaic_0: port@0 {
					reg = <0>;
					v_demosaic_0mipi_csi2_rx_subsyst_0: endpoint {
						remote-endpoint = <&mipi_csirx_outmipi_csi2_rx_subsyst_0>;
					};
				};
			};
		};
		v_demosaic_1: v_demosaic@80040000 {
			compatible = "xlnx,v-demosaic-1.1" , "xlnx,v-demosaic";
			xlnx,max-width = <1920>;
			xlnx,max-height = <1080>;
			xlnx,max-rows = <1080>;
			xlnx,use-uram = <0>;
			xlnx,ip-name = "v_demosaic";
			reg = <0x0 0x80040000 0x0 0x10000>;
			clocks = <&zynqmp_clk 71>;
			xlnx,s-axi-ctrl-addr-width = <6>;
			xlnx,enable-zipper-removal;
			xlnx,samples-per-clock = <1>;
			xlnx,max-data-width = <10>;
			xlnx,edk-iptype = "PERIPHERAL";
			xlnx,max-cols = <1920>;
			status = "okay";
			clock-names = "ap_clk";
			xlnx,algorithm = <0>;
			xlnx,s-axi-ctrl-data-width = <32>;
			xlnx,name = "v_demosaic_1";
			demosaic_portsv_demosaic_1: ports {
				#address-cells = <1>;
				#size-cells = <0>;
				demosaic_port1v_demosaic_1: port@1 {
					reg = <1>;
					demo_outv_demosaic_1: endpoint {
						remote-endpoint = <&v_gamma_lut_1v_demosaic_1>;
					};
				};
				demosaic_port0v_demosaic_1: port@0 {
					reg = <0>;
					v_demosaic_1mipi_csi2_rx_subsyst_1: endpoint {
						remote-endpoint = <&mipi_csirx_outmipi_csi2_rx_subsyst_1>;
					};
				};
			};
		};
		v_gamma_lut_0: v_gamma_lut@80070000 {
			compatible = "xlnx,v-gamma-lut-1.1" , "xlnx,v-gamma-lut";
			xlnx,max-width = <1920>;
			xlnx,max-height = <1080>;
			xlnx,max-rows = <1080>;
			xlnx,ip-name = "v_gamma_lut";
			reg = <0x0 0x80070000 0x0 0x10000>;
			clocks = <&zynqmp_clk 71>;
			xlnx,s-axi-ctrl-addr-width = <13>;
			xlnx,max-data-width = <10>;
			xlnx,samples-per-clock = <1>;
			xlnx,edk-iptype = "PERIPHERAL";
			xlnx,max-cols = <1920>;
			status = "okay";
			clock-names = "ap_clk";
			xlnx,s-axi-ctrl-data-width = <32>;
			xlnx,name = "v_gamma_lut_0";
			gamma_portsv_gamma_lut_0: ports {
				#address-cells = <1>;
				#size-cells = <0>;
				gamma_port1v_gamma_lut_0: port@1 {
					xlnx,video-width = <10>;
					reg = <1>;
					gamma_outv_gamma_lut_0: endpoint {
						remote-endpoint = <&axi_vdma_0v_gamma_lut_0>;
					};
				};
				gamma_port0v_gamma_lut_0: port@0 {
					xlnx,video-width = <10>;
					reg = <0>;
					v_gamma_lut_0v_demosaic_0: endpoint {
						remote-endpoint = <&demo_outv_demosaic_0>;
					};
				};
			};
		};
		v_gamma_lut_1: v_gamma_lut@80080000 {
			compatible = "xlnx,v-gamma-lut-1.1" , "xlnx,v-gamma-lut";
			xlnx,max-width = <1920>;
			xlnx,max-height = <1080>;
			xlnx,max-rows = <1080>;
			xlnx,ip-name = "v_gamma_lut";
			reg = <0x0 0x80080000 0x0 0x10000>;
			clocks = <&zynqmp_clk 71>;
			xlnx,s-axi-ctrl-addr-width = <13>;
			xlnx,max-data-width = <10>;
			xlnx,samples-per-clock = <1>;
			xlnx,edk-iptype = "PERIPHERAL";
			xlnx,max-cols = <1920>;
			status = "okay";
			clock-names = "ap_clk";
			xlnx,s-axi-ctrl-data-width = <32>;
			xlnx,name = "v_gamma_lut_1";
			gamma_portsv_gamma_lut_1: ports {
				#address-cells = <1>;
				#size-cells = <0>;
				gamma_port1v_gamma_lut_1: port@1 {
					xlnx,video-width = <10>;
					reg = <1>;
					gamma_outv_gamma_lut_1: endpoint {
						remote-endpoint = <&axi_vdma_1v_gamma_lut_1>;
					};
				};
				gamma_port0v_gamma_lut_1: port@0 {
					xlnx,video-width = <10>;
					reg = <0>;
					v_gamma_lut_1v_demosaic_1: endpoint {
						remote-endpoint = <&demo_outv_demosaic_1>;
					};
				};
			};
		};
		mipi_csi2_rx_subsyst_0_phy: mipi_csi2_rx_subsyst_0_phy@1000 {
			xlnx,data-lane2-byte = "All_Byte";
			xlnx,en-dphy-io = <1>;
			xlnx,skewcal-first-time = <4096>;
			xlnx,clk-lane-txif4-io-loc = "AC9";
			xlnx,data-lane1-txif4-io-position = <4>;
			xlnx,data-lane5-io-position = <51>;
			xlnx,hp-io-bank-name = "64_(HP)";
			xlnx,data-lane2-txif3-io-loc = "AD7";
			xlnx,data-lane2-txif2-byte = "All_Byte";
			xlnx,lpx-period = <50>;
			xlnx,en-tx-algo = <0>;
			xlnx,data-lane3-txif3-io-position = <51>;
			xlnx,en-txcalib-sim = <0>;
			xlnx,dphy-lanes = <2>;
			xlnx,data-lane7-io-position = <51>;
			xlnx,data-lane7-io-loc = "None";
			xlnx,data-lane3-txif3-byte = "All_Byte";
			xlnx,data-lane0-txif2-io-loc-name = "IO_L2P_T0L_N2_64";
			xlnx,ip-name = "mipi_dphy";
			xlnx,txif1-instname = "tx64";
			reg = <0x0 0x00001000 0x0 0x1000>;
			xlnx,clk-lane-txif2-io-position = <0>;
			xlnx,data-lane0-txif4-io-loc-name = "IO_L2P_T0L_N2_64";
			xlnx,en-io-sel = <1>;
			xlnx,en-dcts-logic = <0>;
			xlnx,data-lane2-txif3-io-loc-name = "IO_L4P_T0U_N6_DBC_AD7P_64";
			xlnx,clk-lane-txif3-io-loc = "AC9";
			xlnx,clk-lane-txif4-io-position = <0>;
			xlnx,data-lane2-txif2-io-loc = "AD7";
			xlnx,en-ext-tap = <0>;
			xlnx,pll-divclk-divide = <1>;
			xlnx,supportlevel;
			xlnx,data-lane6-io-loc = "None";
			xlnx,tx-output-impedance;
			xlnx,rx-equalization = "EQ_LEVEL4";
			xlnx,clk-lane-io-loc-name = "IO_L1P_T0L_N0_DBC_64";
			xlnx,data-lane7-byte = "All_Byte";
			xlnx,esc-timeout = <25600>;
			xlnx,clk-lane-io-loc = "AC9";
			xlnx,en-debug-tx-calib = <0>;
			xlnx,txif2-instname = "tx64";
			xlnx,clk-lane-txif2-io-loc = "AC9";
			xlnx,data-lane0-txif3-io-position = <2>;
			xlnx,ddr-clk-period = <2>;
			xlnx,data-lane0-txif2-byte = "All_Byte";
			xlnx,txpll-clkin-period = <8>;
			xlnx,en-reg-if = <1>;
			compatible = "xlnx,mipi-dphy-4.3";
			xlnx,data-lane2-txif2-io-position = <51>;
			xlnx,txif2-hp-io-bank-selection = <64>;
			xlnx,en-rxppi-as-mon = <0>;
			xlnx,data-lane5-io-loc = "None";
			xlnx,data-lane4-byte = "All_Byte";
			xlnx,data-lane1-txif4-io-loc = "AB8";
			xlnx,data-lane1-txif3-byte = "All_Byte";
			xlnx,idly-tap = <0>;
			xlnx,data-lane2-txif4-io-position = <51>;
			xlnx,fifo-rd-en-control;
			xlnx,dl0-io-swap = <0>;
			xlnx,txif2-hp-io-bank-name = "64_(HP)";
			xlnx,data-lane2-txif4-byte = "All_Byte";
			xlnx,data-lane1-io-loc-name = "IO_L3P_T0L_N4_AD15P_64";
			xlnx,example-simulation = <1>;
			xlnx,dl1-io-swap = <0>;
			xlnx,txif3-hp-io-bank-name = "64_(HP)";
			xlnx,mtbf-sync-stages = <3>;
			xlnx,hs-timeout = <65541>;
			xlnx,dl2-io-swap = <0>;
			xlnx,txif4-hp-io-bank-name = "64_(HP)";
			xlnx,data-lane3-io-loc-name = "None";
			xlnx,data-lane1-txif2-io-loc-name = "IO_L3P_T0L_N4_AD15P_64";
			xlnx,dl3-io-swap = <0>;
			xlnx,data-lane1-byte = "All_Byte";
			xlnx,dl4-io-swap = <0>;
			xlnx,data-lane5-io-loc-name = "None";
			xlnx,data-lane1-txif4-io-loc-name = "IO_L3P_T0L_N4_AD15P_64";
			xlnx,txif3-instname = "tx64";
			xlnx,pll-clk1-divide = <8>;
			xlnx,cal-mode = "FIXED";
			xlnx,dl5-io-swap = <0>;
			xlnx,data-lane4-io-loc = "None";
			xlnx,data-lane3-txif3-io-loc-name = "IO_L5P_T0U_N8_AD14P_64";
			xlnx,data-lane1-txif3-io-loc = "AB8";
			xlnx,use-lane0-txreadyhs;
			xlnx,dl6-io-swap = <0>;
			xlnx,data-lane7-io-loc-name = "None";
			xlnx,dl7-io-swap = <0>;
			xlnx,data-lane3-txif2-byte = "All_Byte";
			xlnx,wakeup = <1000000>;
			xlnx,versal = <0>;
			status = "okay";
			xlnx,data-lane0-io-position = <2>;
			xlnx,en-txsplt = <0>;
			xlnx,clk-lane-txif2-io-loc-name = "IO_L1P_T0L_N0_DBC_64";
			xlnx,data-lane2-io-position = <51>;
			xlnx,pll-clk0-divide = <8>;
			xlnx,name = "mipi_csi2_rx_subsyst_0_phy";
			xlnx,clk-lane-txif4-io-loc-name = "IO_L1P_T0L_N0_DBC_64";
			xlnx,dphyrx-board-interface = "Custom";
			xlnx,data-lane3-io-loc = "None";
			xlnx,data-lane1-txif2-io-loc = "AB8";
			xlnx,data-lane1-txif3-io-position = <4>;
			xlnx,data-lane4-io-position = <51>;
			xlnx,txif4-instname = "tx64";
			xlnx,txif1-createinst;
			xlnx,data-lane3-txif2-io-position = <51>;
			xlnx,data-lane0-txif4-byte = "All_Byte";
			xlnx,data-lane6-io-position = <51>;
			xlnx,txif4-hp-io-bank-selection = <64>;
			xlnx,data-lane3-txif4-io-position = <51>;
			xlnx,data-lane6-byte = "All_Byte";
			xlnx,data-lane3-txif4-io-loc = "AB7";
			xlnx,hs-settle-ns = <145>;
			xlnx,is-hierarchy;
			xlnx,data-lane0-txif3-io-loc-name = "IO_L2P_T0L_N2_64";
			clocks = <&zynqmp_clk 72>, <&zynqmp_clk 71>;
			xlnx,xiphy-line-rate-min = <600>;
			xlnx,data-lane2-txif2-io-loc-name = "IO_L4P_T0U_N6_DBC_AD7P_64";
			xlnx,data-lane2-io-loc = "None";
			xlnx,en-ssc = <0>;
			xlnx,clk-lane-txif3-io-position = <0>;
			xlnx,stable-clk-period = <5>;
			xlnx,en-clk300m = <0>;
			xlnx,data-lane3-byte = "All_Byte";
			xlnx,data-lane2-txif4-io-loc-name = "IO_L4P_T0U_N6_DBC_AD7P_64";
			xlnx,data-lane1-txif2-byte = "All_Byte";
			xlnx,data-lane0-txif4-io-loc = "AE9";
			xlnx,stretch-line-rate = <3500>;
			xlnx,edk-iptype = "PERIPHERAL";
			xlnx,init = <100000>;
			xlnx,data-lane3-txif3-io-loc = "AB7";
			xlnx,data-lane2-txif3-byte = "All_Byte";
			clock-names = "core_clk" , "s_axi_aclk";
			xlnx,data-lane3-txif4-byte = "All_Byte";
			xlnx,en-hs-obuftds = <0>;
			xlnx,data-lane1-io-loc = "AB8";
			xlnx,data-lane0-byte = "All_Byte";
			xlnx,data-lane0-txif2-io-position = <2>;
			xlnx,hp-io-bank-selection = <64>;
			xlnx,pll-divclk-mult = <8>;
			xlnx,data-lane0-txif3-io-loc = "AE9";
			xlnx,lprx-disable-extport = <0>;
			xlnx,idly-group-name = "mipi_csi2rx_idly_group";
			xlnx,esc-clk-period = <50>;
			xlnx,data-lane0-txif4-io-position = <2>;
			xlnx,highaddr = <0x1fff>;
			xlnx,data-lane2-txif3-io-position = <51>;
			xlnx,dphytx-board-interface = "Custom";
			xlnx,data-lane3-txif2-io-loc = "AB7";
			xlnx,dphy-preset = "CSI2RX_XLNX";
			xlnx,data-lane0-io-loc-name = "IO_L2P_T0L_N2_64";
			xlnx,en-timeout-regs = <0>;
			xlnx,en-7s-linerate-check;
			xlnx,clk-lane-io-position = <0>;
			xlnx,div4-clk-period = <8>;
			xlnx,data-lane2-io-loc-name = "None";
			xlnx,data-lane0-io-loc = "AE9";
			xlnx,data-lane4-io-loc-name = "None";
			xlnx,data-lane1-txif3-io-loc-name = "IO_L3P_T0L_N4_AD15P_64";
			xlnx,data-lane0-txif2-io-loc = "AE9";
			xlnx,hs-line-rate = <1000>;
			xlnx,data-lane3-txif2-io-loc-name = "IO_L5P_T0U_N8_AD14P_64";
			xlnx,skewcal-periodic-time = <128>;
			xlnx,pll-clkoutphy-mode = "VCO";
			xlnx,data-lane6-io-loc-name = "None";
			xlnx,data-lane0-txif3-byte = "All_Byte";
			xlnx,s50-logic = <0>;
			xlnx,txif3-hp-io-bank-selection = <64>;
			xlnx,data-lane3-txif4-io-loc-name = "IO_L5P_T0U_N8_AD14P_64";
			xlnx,tx-riu-wr-gap = <16>;
			xlnx,data-lane5-byte = "All_Byte";
			xlnx,data-lane2-txif4-io-loc = "AD7";
			xlnx,data-lane1-txif4-byte = "All_Byte";
			xlnx,en-debug-regs = <0>;
			xlnx,dphy-mode = <0>;
			xlnx,clk-io-swap = <0>;
			xlnx,data-lane1-io-position = <4>;
			xlnx,en-bufg-on-wr-clk-out;
			xlnx,en-act-lanes = <0>;
			xlnx,dphy-txifs = <1>;
			xlnx,clk-lane-txif3-io-loc-name = "IO_L1P_T0L_N0_DBC_64";
			xlnx,data-lane1-txif2-io-position = <4>;
			xlnx,data-lane3-io-position = <51>;
		};
		mipi_csi2_rx_subsyst_0_rx: mipi_csi2_rx_subsyst_0_rx@0 {
			xlnx,ip-name = "mipi_csi2_rx_ctrl";
			reg = <0x0 0x00000000 0x0 0x1000>;
			xlnx,ppi-sig-width = <0>;
			xlnx,cmn-inc-vfb = <0>;
			xlnx,axis-tuser-width = <96>;
			compatible = "xlnx,mipi-csi2-rx-ctrl-1.0";
			xlnx,cmn-num-pixels = <1>;
			xlnx,cmn-proj-family = <0>;
			xlnx,csi2rx-dbg = <0>;
			xlnx,csi-opt1-regs = <0>;
			xlnx,disable-lite = <0>;
			xlnx,ppi-sync-width = <0>;
			xlnx,csi-filter-userdatatype = <0>;
			xlnx,csi-offload-nonimage = <0>;
			xlnx,csi-vc-off-10 = <11>;
			xlnx,emb-dw = <64>;
			xlnx,csi-vc-off-11 = <12>;
			xlnx,csi-vc-off-12 = <13>;
			status = "okay";
			xlnx,csi-vc-off-13 = <14>;
			xlnx,csi-vc-off-14 = <15>;
			xlnx,ppi-mult = <0>;
			xlnx,name = "mipi_csi2_rx_subsyst_0_rx";
			xlnx,csi-vc-off-0 = <1>;
			xlnx,csi-vc-off-1 = <2>;
			xlnx,csi-vc-off-2 = <3>;
			xlnx,csi-vc-off-3 = <4>;
			xlnx,csi-vc-off-4 = <5>;
			xlnx,csi-lanes = <2>;
			xlnx,csi-vc-off-5 = <6>;
			xlnx,is-hierarchy;
			xlnx,axis-fifo-depth = <2048>;
			xlnx,csi-vc-off-6 = <7>;
			clocks = <&zynqmp_clk 72>, <&misc_clk_0>, <&misc_clk_0>, <&zynqmp_clk 71>, <&zynqmp_clk 71>, <&zynqmp_clk 71>;
			xlnx,axis-fifo-dcnt-width = <11>;
			xlnx,mipi-slv-int = <0>;
			xlnx,csi-vc-off-7 = <8>;
			xlnx,csi-vc-off-8 = <9>;
			xlnx,axis-tdest-width = <4>;
			xlnx,phy-mode = "DPHY";
			xlnx,csi-vc-off-9 = <10>;
			xlnx,edk-iptype = "PERIPHERAL";
			xlnx,cmn-pxl-format = "RAW10";
			xlnx,csi-opt2-crc = <0>;
			clock-names = "core_clk" , "dl0_rxbyteclkhs" , "dl1_rxbyteclkhs" , "m_axis_aclk" , "s_axi_aclk" , "video_aclk";
			xlnx,hp-io-bank-selection = <64>;
			xlnx,csi-opt3-fixedlanes = <1>;
			xlnx,csi-en-vc-support = <1>;
			xlnx,hs-line-rate = <1000>;
			xlnx,csi-fixed-vc = <0>;
			xlnx,csi-inv-shutdown = <1>;
			xlnx,axis-tdata-width = <64>;
			xlnx,header-data-width = <32>;
		};
		mipi_csi2_rx_subsyst_1_phy: mipi_csi2_rx_subsyst_1_phy@1000 {
			xlnx,data-lane2-byte = "All_Byte";
			xlnx,en-dphy-io = <1>;
			xlnx,skewcal-first-time = <4096>;
			xlnx,clk-lane-txif4-io-loc = "AC9";
			xlnx,data-lane1-txif4-io-position = <4>;
			xlnx,data-lane5-io-position = <51>;
			xlnx,hp-io-bank-name = "65_(HP)";
			xlnx,data-lane2-txif3-io-loc = "AD7";
			xlnx,data-lane2-txif2-byte = "All_Byte";
			xlnx,lpx-period = <50>;
			xlnx,en-tx-algo = <0>;
			xlnx,data-lane3-txif3-io-position = <51>;
			xlnx,en-txcalib-sim = <0>;
			xlnx,dphy-lanes = <2>;
			xlnx,data-lane7-io-position = <51>;
			xlnx,data-lane7-io-loc = "None";
			xlnx,data-lane3-txif3-byte = "All_Byte";
			xlnx,data-lane0-txif2-io-loc-name = "IO_L2P_T0L_N2_64";
			xlnx,ip-name = "mipi_dphy";
			xlnx,txif1-instname = "tx65";
			reg = <0x0 0x00001000 0x0 0x1000>;
			xlnx,clk-lane-txif2-io-position = <0>;
			xlnx,data-lane0-txif4-io-loc-name = "IO_L2P_T0L_N2_64";
			xlnx,en-io-sel = <1>;
			xlnx,en-dcts-logic = <0>;
			xlnx,data-lane2-txif3-io-loc-name = "IO_L4P_T0U_N6_DBC_AD7P_64";
			xlnx,clk-lane-txif3-io-loc = "AC9";
			xlnx,clk-lane-txif4-io-position = <0>;
			xlnx,data-lane2-txif2-io-loc = "AD7";
			xlnx,en-ext-tap = <0>;
			xlnx,pll-divclk-divide = <1>;
			xlnx,supportlevel;
			xlnx,data-lane6-io-loc = "None";
			xlnx,tx-output-impedance;
			xlnx,rx-equalization = "EQ_LEVEL4";
			xlnx,clk-lane-io-loc-name = "IO_L1P_T0L_N0_DBC_65";
			xlnx,data-lane7-byte = "All_Byte";
			xlnx,esc-timeout = <25600>;
			xlnx,clk-lane-io-loc = "W8";
			xlnx,en-debug-tx-calib = <0>;
			xlnx,txif2-instname = "tx64";
			xlnx,clk-lane-txif2-io-loc = "AC9";
			xlnx,data-lane0-txif3-io-position = <2>;
			xlnx,ddr-clk-period = <2>;
			xlnx,data-lane0-txif2-byte = "All_Byte";
			xlnx,txpll-clkin-period = <8>;
			xlnx,en-reg-if = <1>;
			compatible = "xlnx,mipi-dphy-4.3";
			xlnx,data-lane2-txif2-io-position = <51>;
			xlnx,txif2-hp-io-bank-selection = <64>;
			xlnx,en-rxppi-as-mon = <0>;
			xlnx,data-lane5-io-loc = "None";
			xlnx,data-lane4-byte = "All_Byte";
			xlnx,data-lane1-txif4-io-loc = "AB8";
			xlnx,data-lane1-txif3-byte = "All_Byte";
			xlnx,idly-tap = <0>;
			xlnx,data-lane2-txif4-io-position = <51>;
			xlnx,fifo-rd-en-control;
			xlnx,dl0-io-swap = <0>;
			xlnx,txif2-hp-io-bank-name = "64_(HP)";
			xlnx,data-lane2-txif4-byte = "All_Byte";
			xlnx,data-lane1-io-loc-name = "IO_L3P_T0L_N4_AD15P_65";
			xlnx,example-simulation = <1>;
			xlnx,dl1-io-swap = <0>;
			xlnx,txif3-hp-io-bank-name = "64_(HP)";
			xlnx,mtbf-sync-stages = <3>;
			xlnx,hs-timeout = <65541>;
			xlnx,dl2-io-swap = <0>;
			xlnx,txif4-hp-io-bank-name = "64_(HP)";
			xlnx,data-lane3-io-loc-name = "None";
			xlnx,data-lane1-txif2-io-loc-name = "IO_L3P_T0L_N4_AD15P_64";
			xlnx,dl3-io-swap = <0>;
			xlnx,data-lane1-byte = "All_Byte";
			xlnx,dl4-io-swap = <0>;
			xlnx,data-lane5-io-loc-name = "None";
			xlnx,data-lane1-txif4-io-loc-name = "IO_L3P_T0L_N4_AD15P_64";
			xlnx,txif3-instname = "tx64";
			xlnx,pll-clk1-divide = <8>;
			xlnx,cal-mode = "FIXED";
			xlnx,dl5-io-swap = <0>;
			xlnx,data-lane4-io-loc = "None";
			xlnx,data-lane3-txif3-io-loc-name = "IO_L5P_T0U_N8_AD14P_64";
			xlnx,data-lane1-txif3-io-loc = "AB8";
			xlnx,use-lane0-txreadyhs;
			xlnx,dl6-io-swap = <0>;
			xlnx,data-lane7-io-loc-name = "None";
			xlnx,dl7-io-swap = <0>;
			xlnx,data-lane3-txif2-byte = "All_Byte";
			xlnx,wakeup = <1000000>;
			xlnx,versal = <0>;
			status = "okay";
			xlnx,data-lane0-io-position = <2>;
			xlnx,en-txsplt = <0>;
			xlnx,clk-lane-txif2-io-loc-name = "IO_L1P_T0L_N0_DBC_64";
			xlnx,data-lane2-io-position = <51>;
			xlnx,pll-clk0-divide = <8>;
			xlnx,name = "mipi_csi2_rx_subsyst_1_phy";
			xlnx,clk-lane-txif4-io-loc-name = "IO_L1P_T0L_N0_DBC_64";
			xlnx,dphyrx-board-interface = "Custom";
			xlnx,data-lane3-io-loc = "None";
			xlnx,data-lane1-txif2-io-loc = "AB8";
			xlnx,data-lane1-txif3-io-position = <4>;
			xlnx,data-lane4-io-position = <51>;
			xlnx,txif4-instname = "tx64";
			xlnx,txif1-createinst;
			xlnx,data-lane3-txif2-io-position = <51>;
			xlnx,data-lane0-txif4-byte = "All_Byte";
			xlnx,data-lane6-io-position = <51>;
			xlnx,txif4-hp-io-bank-selection = <64>;
			xlnx,data-lane3-txif4-io-position = <51>;
			xlnx,data-lane6-byte = "All_Byte";
			xlnx,data-lane3-txif4-io-loc = "AB7";
			xlnx,hs-settle-ns = <145>;
			xlnx,is-hierarchy;
			xlnx,data-lane0-txif3-io-loc-name = "IO_L2P_T0L_N2_64";
			clocks = <&zynqmp_clk 72>, <&zynqmp_clk 71>;
			xlnx,xiphy-line-rate-min = <600>;
			xlnx,data-lane2-txif2-io-loc-name = "IO_L4P_T0U_N6_DBC_AD7P_64";
			xlnx,data-lane2-io-loc = "None";
			xlnx,en-ssc = <0>;
			xlnx,clk-lane-txif3-io-position = <0>;
			xlnx,stable-clk-period = <5>;
			xlnx,en-clk300m = <0>;
			xlnx,data-lane3-byte = "All_Byte";
			xlnx,data-lane2-txif4-io-loc-name = "IO_L4P_T0U_N6_DBC_AD7P_64";
			xlnx,data-lane1-txif2-byte = "All_Byte";
			xlnx,data-lane0-txif4-io-loc = "AE9";
			xlnx,stretch-line-rate = <3500>;
			xlnx,edk-iptype = "PERIPHERAL";
			xlnx,init = <100000>;
			xlnx,data-lane3-txif3-io-loc = "AB7";
			xlnx,data-lane2-txif3-byte = "All_Byte";
			clock-names = "core_clk" , "s_axi_aclk";
			xlnx,data-lane3-txif4-byte = "All_Byte";
			xlnx,en-hs-obuftds = <0>;
			xlnx,data-lane1-io-loc = "U8";
			xlnx,data-lane0-byte = "All_Byte";
			xlnx,data-lane0-txif2-io-position = <2>;
			xlnx,hp-io-bank-selection = <65>;
			xlnx,pll-divclk-mult = <8>;
			xlnx,data-lane0-txif3-io-loc = "AE9";
			xlnx,lprx-disable-extport = <0>;
			xlnx,idly-group-name = "mipi_csi2rx_idly_group";
			xlnx,esc-clk-period = <50>;
			xlnx,data-lane0-txif4-io-position = <2>;
			xlnx,highaddr = <0x1fff>;
			xlnx,data-lane2-txif3-io-position = <51>;
			xlnx,dphytx-board-interface = "Custom";
			xlnx,data-lane3-txif2-io-loc = "AB7";
			xlnx,dphy-preset = "CSI2RX_XLNX";
			xlnx,data-lane0-io-loc-name = "IO_L2P_T0L_N2_65";
			xlnx,en-timeout-regs = <0>;
			xlnx,en-7s-linerate-check;
			xlnx,clk-lane-io-position = <0>;
			xlnx,div4-clk-period = <8>;
			xlnx,data-lane2-io-loc-name = "None";
			xlnx,data-lane0-io-loc = "U9";
			xlnx,data-lane4-io-loc-name = "None";
			xlnx,data-lane1-txif3-io-loc-name = "IO_L3P_T0L_N4_AD15P_64";
			xlnx,data-lane0-txif2-io-loc = "AE9";
			xlnx,hs-line-rate = <1000>;
			xlnx,data-lane3-txif2-io-loc-name = "IO_L5P_T0U_N8_AD14P_64";
			xlnx,skewcal-periodic-time = <128>;
			xlnx,pll-clkoutphy-mode = "VCO";
			xlnx,data-lane6-io-loc-name = "None";
			xlnx,data-lane0-txif3-byte = "All_Byte";
			xlnx,s50-logic = <0>;
			xlnx,txif3-hp-io-bank-selection = <64>;
			xlnx,data-lane3-txif4-io-loc-name = "IO_L5P_T0U_N8_AD14P_64";
			xlnx,tx-riu-wr-gap = <16>;
			xlnx,data-lane5-byte = "All_Byte";
			xlnx,data-lane2-txif4-io-loc = "AD7";
			xlnx,data-lane1-txif4-byte = "All_Byte";
			xlnx,en-debug-regs = <0>;
			xlnx,dphy-mode = <0>;
			xlnx,clk-io-swap = <0>;
			xlnx,data-lane1-io-position = <4>;
			xlnx,en-bufg-on-wr-clk-out;
			xlnx,en-act-lanes = <0>;
			xlnx,dphy-txifs = <1>;
			xlnx,clk-lane-txif3-io-loc-name = "IO_L1P_T0L_N0_DBC_64";
			xlnx,data-lane1-txif2-io-position = <4>;
			xlnx,data-lane3-io-position = <51>;
		};
		mipi_csi2_rx_subsyst_1_rx: mipi_csi2_rx_subsyst_1_rx@0 {
			xlnx,ip-name = "mipi_csi2_rx_ctrl";
			reg = <0x0 0x00000000 0x0 0x1000>;
			xlnx,ppi-sig-width = <0>;
			xlnx,cmn-inc-vfb = <0>;
			xlnx,axis-tuser-width = <96>;
			compatible = "xlnx,mipi-csi2-rx-ctrl-1.0";
			xlnx,cmn-num-pixels = <1>;
			xlnx,cmn-proj-family = <0>;
			xlnx,csi2rx-dbg = <0>;
			xlnx,csi-opt1-regs = <0>;
			xlnx,disable-lite = <0>;
			xlnx,ppi-sync-width = <0>;
			xlnx,csi-filter-userdatatype = <0>;
			xlnx,csi-offload-nonimage = <0>;
			xlnx,csi-vc-off-10 = <11>;
			xlnx,emb-dw = <64>;
			xlnx,csi-vc-off-11 = <12>;
			xlnx,csi-vc-off-12 = <13>;
			status = "okay";
			xlnx,csi-vc-off-13 = <14>;
			xlnx,csi-vc-off-14 = <15>;
			xlnx,ppi-mult = <0>;
			xlnx,name = "mipi_csi2_rx_subsyst_1_rx";
			xlnx,csi-vc-off-0 = <1>;
			xlnx,csi-vc-off-1 = <2>;
			xlnx,csi-vc-off-2 = <3>;
			xlnx,csi-vc-off-3 = <4>;
			xlnx,csi-vc-off-4 = <5>;
			xlnx,csi-lanes = <2>;
			xlnx,csi-vc-off-5 = <6>;
			xlnx,is-hierarchy;
			xlnx,axis-fifo-depth = <2048>;
			xlnx,csi-vc-off-6 = <7>;
			clocks = <&zynqmp_clk 72>, <&misc_clk_0>, <&misc_clk_0>, <&zynqmp_clk 71>, <&zynqmp_clk 71>, <&zynqmp_clk 71>;
			xlnx,axis-fifo-dcnt-width = <11>;
			xlnx,mipi-slv-int = <0>;
			xlnx,csi-vc-off-7 = <8>;
			xlnx,csi-vc-off-8 = <9>;
			xlnx,axis-tdest-width = <4>;
			xlnx,phy-mode = "DPHY";
			xlnx,csi-vc-off-9 = <10>;
			xlnx,edk-iptype = "PERIPHERAL";
			xlnx,cmn-pxl-format = "RAW10";
			xlnx,csi-opt2-crc = <0>;
			clock-names = "core_clk" , "dl0_rxbyteclkhs" , "dl1_rxbyteclkhs" , "m_axis_aclk" , "s_axi_aclk" , "video_aclk";
			xlnx,hp-io-bank-selection = <65>;
			xlnx,csi-opt3-fixedlanes = <1>;
			xlnx,csi-en-vc-support = <1>;
			xlnx,hs-line-rate = <1000>;
			xlnx,csi-fixed-vc = <0>;
			xlnx,csi-inv-shutdown = <1>;
			xlnx,axis-tdata-width = <64>;
			xlnx,header-data-width = <32>;
		};
	};
};
